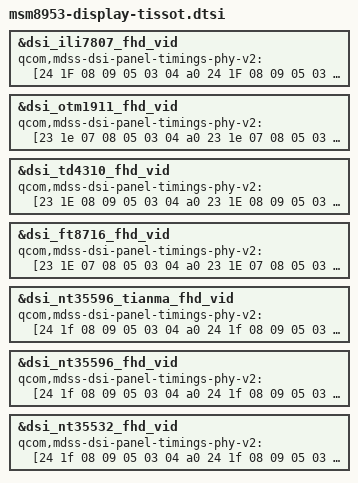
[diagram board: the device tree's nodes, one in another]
 /* Copyright (c) 2017, The Linux Foundation. All rights reserved.
  *
  * This program is free software; you can redistribute it and/or modify
  * it under the terms of the GNU General Public License version 2 and
  * only version 2 as published by the Free Software Foundation.
  *
  * This program is distributed in the hope that it will be useful,
  * but WITHOUT ANY WARRANTY; without even the implied warranty of
  * MERCHANTABILITY or FITNESS FOR A PARTICULAR PURPOSE.  See the
  * GNU General Public License for more details.
  */

&dsi_ili7807_fhd_vid {
	qcom,mdss-dsi-panel-timings-phy-v2 = [24 1F 08 09 05 03 04 a0
		24 1F 08 09 05 03 04 a0
		24 1F 08 09 05 03 04 a0
		24 1F 08 09 05 03 04 a0
		24 1B 08 09 05 03 04 a0];
};

&dsi_otm1911_fhd_vid {
	qcom,mdss-dsi-panel-timings-phy-v2 = [23 1e 07 08 05 03 04 a0
		23 1e 07 08 05 03 04 a0
		23 1e 07 08 05 03 04 a0
		23 1e 07 08 05 03 04 a0
		23 18 07 08 05 03 04 a0];
};

&dsi_td4310_fhd_vid {
	qcom,mdss-dsi-panel-timings-phy-v2 = [23 1E 08 09 05 03 04 a0
		23 1E 08 09 05 03 04 a0
		23 1E 08 09 05 03 04 a0
		23 1E 08 09 05 03 04 a0
		23 1A 08 09 05 03 04 a0];
};

&dsi_ft8716_fhd_vid {
	qcom,mdss-dsi-panel-timings-phy-v2 = [23 1E 07 08 05 03 04 a0
		23 1E 07 08 05 03 04 a0
		23 1E 07 08 05 03 04 a0
		23 1E 07 08 05 03 04 a0
		23 18 07 08 05 03 04 a0];
};

&dsi_nt35596_tianma_fhd_vid {
	qcom,mdss-dsi-panel-timings-phy-v2 = [24 1f 08 09 05 03 04 a0
		24 1f 08 09 05 03 04 a0
		24 1f 08 09 05 03 04 a0
		24 1f 08 09 05 03 04 a0
		24 1b 08 08 05 03 04 a0];
};

&dsi_nt35596_fhd_vid {
	qcom,mdss-dsi-panel-timings-phy-v2 = [24 1f 08 09 05 03 04 a0
		24 1f 08 09 05 03 04 a0
		24 1f 08 09 05 03 04 a0
		24 1f 08 09 05 03 04 a0
	        24 1b 08 08 05 03 04 a0];
};

&dsi_nt35532_fhd_vid {
	qcom,mdss-dsi-panel-timings-phy-v2 = [24 1f 08 09 05 03 04 a0
		24 1f 08 09 05 03 04 a0
		24 1f 08 09 05 03 04 a0
		24 1f 08 09 05 03 04 a0
		24 1b 08 09 05 03 04 a0];
};
